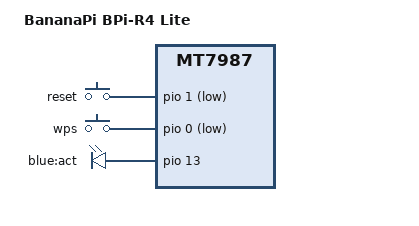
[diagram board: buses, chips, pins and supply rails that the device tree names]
// SPDX-License-Identifier: (GPL-2.0 OR MIT)

#include "mt7987a.dtsi"
#include <dt-bindings/input/input.h>

/ {
	model = "BananaPi BPi-R4 Lite";
	compatible = "mediatek,mt7987a", "mediatek,mt7987";

	gpio-keys {
		compatible = "gpio-keys";

		reset {
			label = "reset";
			linux,code = <KEY_RESTART>;
			gpios = <&pio 1 GPIO_ACTIVE_LOW>;
			debounce-interval = <10>;
		};

		wps {
			label = "wps";
			linux,code = <KEY_WPS_BUTTON>;
			gpios = <&pio 0 GPIO_ACTIVE_LOW>;
			debounce-interval = <10>;
		};
	};

	gpio-leds {
		compatible = "gpio-leds";

		act {
			label = "blue:act";
			gpios = <&pio 13 GPIO_ACTIVE_HIGH>;
		};
	};
};
